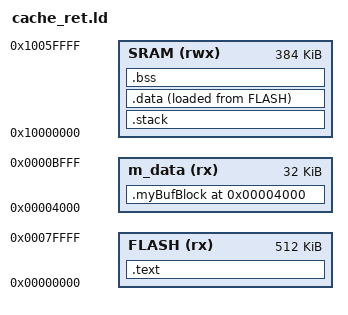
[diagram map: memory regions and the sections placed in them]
/******************************************************************************
 *
 * cache_ret.ld - Linker script for applications using startup_gnu.c
 *
 *****************************************************************************/
ENTRY(am_reset_isr)

MEMORY
{
    FLASH (rx) : ORIGIN = 0x00000000, LENGTH = 512K
    m_data (rx) : ORIGIN = 0x4000, LENGTH = 32K
    SRAM (rwx) : ORIGIN = 0x10000000, LENGTH = 384K
}

SECTIONS
{
    .text :
    {
        . = ALIGN(4);
        KEEP(*(.isr_vector))
        *(.text)
        *(.text*)
        *(.rodata)
        *(.rodata*)
        . = ALIGN(4);
        _etext = .;
    } > FLASH

  /* User stack section initialized by startup code. */
  .stack (NOLOAD):
    {
        . = ALIGN(8);
        *(.stack)
        *(.stack*)
        . = ALIGN(8);
    } > SRAM

    .data :
    {
        . = ALIGN(4);
        _sdata = .;
        *(.data)
        *(.data*)
        . = ALIGN(4);
        _edata = .;
    } > SRAM AT>FLASH

    .myBufBlock 0x4000 :
    {
        KEEP(*(.myBufSection)) 
    } > m_data

    /* used by startup to initialize data */
    _init_data = LOADADDR(.data);

    .bss :
    {
        . = ALIGN(4);
        _sbss = .;
        *(.bss)
        *(.bss*)
        *(COMMON)
        . = ALIGN(4);
        _ebss = .;
    } > SRAM

  .ARM.attributes 0 : { *(.ARM.attributes) }
}
